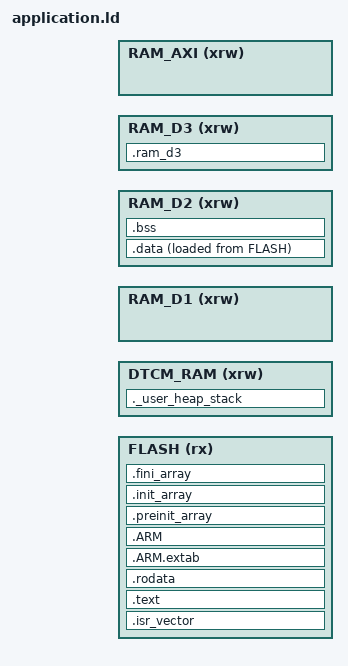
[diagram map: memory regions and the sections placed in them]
/*
******************************************************************************
**

**  File        : STM32H750XBHx_FLASH.ld
**
**
**
**  Abstract    : Linker script for STM32H7 series
**                128Kbytes FLASH and 192Kbytes DTCM_RAM
**
**                Set heap size, stack size and stack location according
**                to application requirements.
**
**                Set memory bank area and size if external memory is used.
**
**  Target      : STMicroelectronics STM32
**
**  Distribution: The file is distributed �as is,� without any warranty
**                of any kind.
**
*****************************************************************************
** @attention
**
** Copyright (c) 2019 STMicroelectronics.
** All rights reserved.
**
** This software component is licensed by ST under BSD 3-Clause license,
** the "License"; You may not use this file except in compliance with the
** License. You may obtain a copy of the License at:
**                        opensource.org/licenses/BSD-3-Clause
**
****************************************************************************
*/
#include "mem_map.h"

/* Entry Point */
ENTRY(Reset_Handler)

/* Highest address of the user mode stack */
_estack = STACK_BASE_ADDR;    /* end of DTCM_RAM */
/* Generate a link error if heap and stack don't fit into DTCM_RAM */
_Min_Heap_Size = HEAP_SIZE;      /* required amount of heap  */
_Min_Stack_Size = STACK_SIZE; /* required amount of stack */

/* Specify the memory areas */
MEMORY
{
FLASH (rx)          : ORIGIN = APP_FLASH_ADDRESS, LENGTH = APP_MAX_SIZE
DTCM_RAM (xrw)      : ORIGIN = RAM_DTCM_ADDRESS, LENGTH = RAM_DTCM_SIZE
RAM_D1 (xrw)        : ORIGIN = RAM_AXI_ADDRESS, LENGTH = RAM_AXI_SIZE
RAM_D2 (xrw)        : ORIGIN = RAM_SRAM123_ADDRESS, LENGTH = RAM_SRAM123_SIZE
RAM_D3 (xrw)        : ORIGIN = RAM_SRAM4_ADDRESS, LENGTH = RAM_SRAM4_SIZE
RAM_AXI (xrw)       : ORIGIN = RAM_AXI_ADDRESS, LENGTH = RAM_AXI_SIZE
}

/* Define output sections */
SECTIONS
{
  /* The startup code goes first into FLASH */
  .isr_vector :
  {
    . = ALIGN(4);
    KEEP(*(.isr_vector)) /* Startup code */
    . = ALIGN(4);
  } >FLASH

  /* The program code and other data goes into FLASH */
  .text :
  {
    . = ALIGN(4);
    *(.text)           /* .text sections (code) */
    *(.text*)          /* .text* sections (code) */
    *(.glue_7)         /* glue arm to thumb code */
    *(.glue_7t)        /* glue thumb to arm code */
    *(.eh_frame)

    KEEP (*(.init))
    KEEP (*(.fini))

    . = ALIGN(4);
    _etext = .;        /* define a global symbols at end of code */
  } >FLASH

  /* Constant data goes into FLASH */
  .rodata :
  {
    . = ALIGN(4);
    *(.rodata)         /* .rodata sections (constants, strings, etc.) */
    *(.rodata*)        /* .rodata* sections (constants, strings, etc.) */
    . = ALIGN(4);
  } >FLASH

  .ARM.extab   : { *(.ARM.extab* .gnu.linkonce.armextab.*) } >FLASH
  .ARM : {
    __exidx_start = .;
    *(.ARM.exidx*)
    __exidx_end = .;
  } >FLASH

  .preinit_array     :
  {
    PROVIDE_HIDDEN (__preinit_array_start = .);
    KEEP (*(.preinit_array*))
    PROVIDE_HIDDEN (__preinit_array_end = .);
  } >FLASH

  .init_array :
  {
    PROVIDE_HIDDEN (__init_array_start = .);
    KEEP (*(SORT(.init_array.*)))
    KEEP (*(.init_array*))
    PROVIDE_HIDDEN (__init_array_end = .);
  } >FLASH
  .fini_array :
  {
    PROVIDE_HIDDEN (__fini_array_start = .);
    KEEP (*(SORT(.fini_array.*)))
    KEEP (*(.fini_array*))
    PROVIDE_HIDDEN (__fini_array_end = .);
  } >FLASH

  /* used by the startup to initialize data */
  _sidata = LOADADDR(.data);

  /* Initialized data sections goes into RAM_D2, load LMA copy after code */
  .data : 
  {
    . = ALIGN(4);
    _sdata = .;        /* create a global symbol at data start */
    *(.data)           /* .data sections */
    *(.data*)          /* .data* sections */

    . = ALIGN(4);
    _edata = .;        /* define a global symbol at data end */
  } >RAM_D2 AT> FLASH

  /* Flash image size */
  _isize = _sidata + SIZEOF(.data) - LOADADDR(.isr_vector);
  /* Uninitialized data section */
  . = ALIGN(4);
  .bss :
  {
    /* This is used by the startup in order to initialize the .bss secion */
    _sbss = .;         /* define a global symbol at bss start */
    __bss_start__ = _sbss;
    *(.bss)
    *(.bss*)
    *(COMMON)

    . = ALIGN(4);
    _ebss = .;         /* define a global symbol at bss end */
    __bss_end__ = _ebss;
  } >RAM_D2

  /* User_heap_stack section, used to check that there is enough RAM_AXI left */
  ._user_heap_stack :
  {
    . = ALIGN(8);
    PROVIDE ( end = . );
    PROVIDE ( _end = . );
    . = . + _Min_Heap_Size;
    . = . + _Min_Stack_Size;
    . = ALIGN(8);
  } >DTCM_RAM

  /* Large buffers or specific data in SRAM4 */
  .ram_d3 (NOLOAD) :
  {
    . = ALIGN(8);
    _sram_d3 = .; /* Start of SRAM4 section */
    *(.ram_d3*)   /* Place all .ram_d3 sections here */
    _eram_d3 = .; /* End of SRAM4 section */
  } > RAM_D3

  /* Remove information from the standard libraries */
  /DISCARD/ :
  {
    libc.a ( * )
    libm.a ( * )
    libgcc.a ( * )
  }

  .ARM.attributes 0 : { *(.ARM.attributes) }
}

